# ESP32-C5-LP register map
Vendor: ESPRESSIF SYSTEMS (SHANGHAI) CO., LTD.; Series: ESP32 C-Series; File version: 1
CPU: RV32IMAC r0p0, little endian, no MPU, no FPU, 0 interrupt priority bits
Address unit: 32 bits
Registers are 32-bit, read-write, reset 0x0 unless marked. A register's access mark holds for its fields unless they carry their own. Offsets are from the block's base; [hi:lo] are bit positions; {n}, {i} and the like mark numbered series.

## LP_IO — LP_IO Peripheral
Base 0x600B4400
0x04 OUT — LP GPIO output register
  [7:0] DATA_ORIG — Configures the output of GPIO0 ~ GPIO7.\\ 0: Low level\\ 1: High level\\ bit0 ~ bit7 are corresponding to GPIO0 ~ GPIO7.\\
0x08 OUT_W1TS wo — LP GPIO output set register
  [7:0] OUT_W1TS — Configures whether or not to enable the output register LP_IO_OUT_REG of GPIO0 ~ GPIO7.\\ - bit0 ~ bit7 are corresponding to GPIO0 ~ GPIO7. - If the value 1 is written to a bit here, the corresponding bit in LP_IO_OUT_REG will be set to 1. - Recommended operation: use this register to set LP_IO_OUT_REG.
0x0C OUT_W1TC wo — LP GPIO output clear register
  [7:0] OUT_W1TC — Configures whether or not to clear the output register LP_IO_OUT_REG of GPIO0 ~ GPIO7.\\ - bit0 ~ bit7 are corresponding to GPIO0 ~ GPIO7. - If the value 1 is written to a bit here, the corresponding bit in LP_IO_OUT_REG will be cleared. - Recommended operation: use this register to clear LP_IO_OUT_REG.
0x10 ENABLE — LP GPIO output enable register
  [7:0] DATA — Configures whether or not to enable the output of GPIO0 ~ GPIO7.\\ 0: Not enable\\ 1: Enable\\ bit0 ~ bit7 are corresponding to GPIO0 ~ GPIO7.\\
0x14 ENABLE_W1TS wo — LP GPIO output enable set register
  [7:0] ENABLE_W1TS — Configures whether or not to set the output enable register LP_IO_ENABLE_REG of GPIO0 ~ GPIO7.\\ - bit0 ~ bit7 are corresponding to GPIO0 ~ GPIO7. - If the value 1 is written to a bit here, the corresponding bit in LP_IO_ENABLE_REG will be set to 1. - Recommended operation: use this register to set LP_IO_ENABLE_REG.
0x18 ENABLE_W1TC wo — LP GPIO output enable clear register
  [7:0] ENABLE_W1TC — Configures whether or not to clear the output enable register LP_IO_ENABLE_REG of GPIO0 ~ GPIO7.\\ - bit0 ~ bit7 are corresponding to GPIO0 ~ GPIO7. - If the value 1 is written to a bit here, the corresponding bit in LP_IO_ENABLE_REG will be cleared. - Recommended operation: use this register to clear LP_IO_ENABLE_REG.
0x1C IN ro — LP GPIO input register
  [7:0] DATA_NEXT — Represents the input value of GPIO0 ~ GPIO7.\\ 0: Low level input\\ 1: High level input\\ bit0 ~ bit7 are corresponding to GPIO0 ~ GPIO7.\\
0x20 STATUS — LP GPIO interrupt status register
  [7:0] INTERRUPT — Configures the interrupt status of GPIO0 ~ GPIO7.\\ 0: No interrupt\\ 1: Interrupt is triggered\\ Bit0 is corresponding to GPIO0, bit1 is corresponding to GPIO1, and etc. This register is used together LP_IO_PIN0_INT_TYPE in register LP_IO_PIN0_REG.\\
0x24 STATUS_W1TS wo — LP GPIO interrupt status set register
  [7:0] STATUS_W1TS — Configures whether or not to set the interrupt status register LP_IO_STATUS_INT of GPIO0 ~ GPIO7.\\ - Bit0 is corresponding to GPIO0, bit1 is corresponding to GPIO1, and etc. - If the value 1 is written to a bit here, the corresponding bit in LP_IO_STATUS_INT will be set to 1. - Recommended operation: use this register to set LP_IO_STATUS_INT.
0x28 STATUS_W1TC wo — LP GPIO interrupt status clear register
  [7:0] STATUS_W1TC — Configures whether or not to clear the interrupt status register LP_IO_STATUS_INT of GPIO0 ~ GPIO7. \\ - Bit0 is corresponding to GPIO0, bit1 is corresponding to GPIO1, and etc. - If the value 1 is written to a bit here, the corresponding bit in LP_IO_STATUS_INT will be cleared - ecommended operation: use this register to clear LP_IO_STATUS_INT.
0x2C STATUS_NEXT ro — LP GPIO interrupt source register
  [7:0] STATUS_INTERRUPT_NEXT — Represents the interrupt source status of GPIO0 ~ GPIO7.\\ bit0 ~ bit7 are corresponding to GPIO0 ~ 7. Each bit represents:\\ 0: Interrupt source status is invalid.\\ 1: Interrupt source status is valid.\\ The interrupt here can be rising-edge triggered, falling-edge triggered, any edge triggered, or level triggered.\\
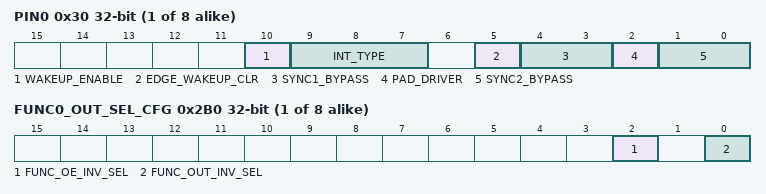
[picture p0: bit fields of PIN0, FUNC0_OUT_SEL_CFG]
{0x30+4i} PIN{i} access per field (i=0..7) — LP GPIO{i} configuration register
  [10] WAKEUP_ENABLE rw — Configures whether or not to enable GPIO{i} wake-up function.\\ 0: Not enable\\ 1: Enable\\ This function is disabled when PD_LP_PERI is powered off.\\
  [9:7] INT_TYPE rw — Configures GPIO{i} interrupt type.\\ 0: GPIO interrupt disabled \\ 1: Rising edge trigger \\ 2: Falling edge trigger \\ 3: Any edge trigger \\ 4: Low level trigger \\ 5: High level trigger \\
  [5] EDGE_WAKEUP_CLR wo — Configures whether or not to clear the edge wake-up status of GPIO0 ~ GPIO7.\\ - bit0 ~ bit7 are corresponding to GPIO0 ~ GPIO7. - If the value 1 is written to a bit here, the edge wake-up status of corresponding GPIO will be cleared.
  [4:3] SYNC1_BYPASS rw — Configures whether or not to synchronize GPIO input data on either edge of LP IO MUX operating clock for the first-level synchronization.\\ 0: Not synchronize\\ 1: Synchronize on falling edge\\ 2: Synchronize on rising edge\\ 3: Synchronize on rising edge\\
  [2] PAD_DRIVER rw — Configures to select the pin dirve mode of GPIO{i}.\\ 0: Normal output\\ 1: Open drain output\\
  [1:0] SYNC2_BYPASS rw — Configures whether or not to synchronize GPIO input data on either edge of LP IO MUX operating clock for the second-level synchronization.\\ 0: Not synchronize\\ 1: Synchronize on falling edge\\ 2: Synchronize on rising edge\\ 3: Synchronize on rising edge\\
{0x2B0+4i} FUNC{i}_OUT_SEL_CFG (i=0..7) — Configuration register for GPIO{i} output
  [2] FUNC_OE_INV_SEL — Configures whether or not to invert the output enable signal.\\ 0: Not invert\\ 1: Invert\\
  [0] FUNC_OUT_INV_SEL — Configures whether or not to invert the output value.\\ 0: Not invert\\ 1: Invert\\
0x3F8 CLOCK_GATE reset 0x1 — GPIO clock gate register
  [0] CLK_EN — set this bit to enable GPIO clock gate.\\
0x3FC DATE reset 0x2312010 — GPIO version register
  [27:0] DATE — version register.\\
